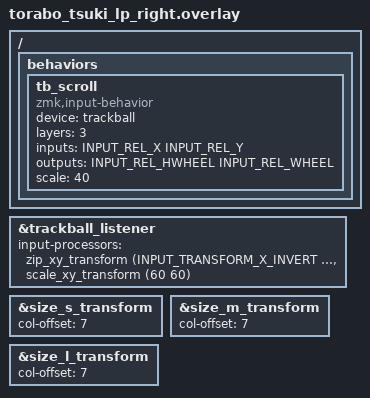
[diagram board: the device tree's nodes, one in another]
#include "torabo_tsuki_lp.dtsi"
#include <input/processors.dtsi>
#include <dt-bindings/zmk/input_transform.h>

/ {
    behaviors {
        tb_scroll: tb_scroll {
            compatible = "zmk,input-behavior";
            #binding-cells = <0>;

            device = <&trackball>;
            layers = <3>;

            inputs  = <INPUT_REL_X INPUT_REL_Y>;
            outputs = <INPUT_REL_HWHEEL INPUT_REL_WHEEL>;

            scale = <40>;
        };
    };
};

&trackball_listener {
    input-processors = <
        &zip_xy_transform (INPUT_TRANSFORM_X_INVERT | INPUT_TRANSFORM_Y_INVERT)
    >,
    <&scale_xy_transform (60 60)>;
};

&size_s_transform {
    col-offset = <7>;
};

&size_m_transform {
    col-offset = <7>;
};

&size_l_transform {
    col-offset = <7>;
};
